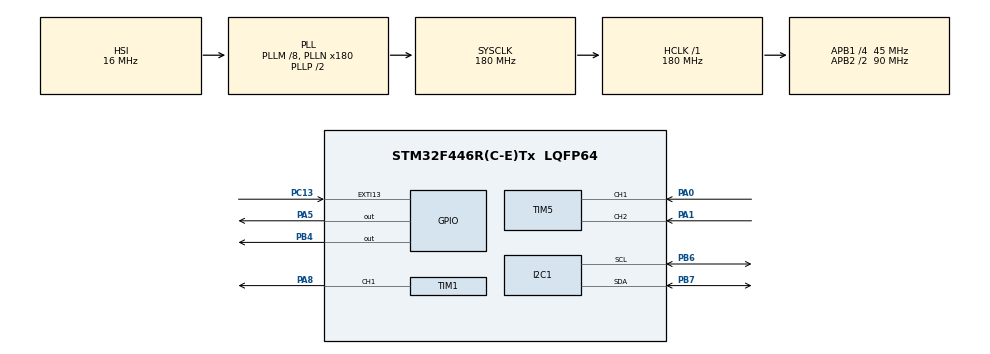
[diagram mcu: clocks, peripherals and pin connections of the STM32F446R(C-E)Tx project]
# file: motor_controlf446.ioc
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Mcu.Family=STM32F4
Mcu.Name=STM32F446R(C-E)Tx
Mcu.Package=LQFP64
NUCLEO-F446RE.BUTTON=1
NUCLEO-F446RE.LD1=true
NVIC.EXTI15_10_IRQn=true\:0\:0\:false\:false\:true\:false\:true\:true
NVIC.PriorityGroup=NVIC_PRIORITYGROUP_0
NVIC.TIM6_DAC_IRQn=true\:0\:0\:false\:false\:true\:true\:true\:true
PA0-WKUP.Signal=S_TIM5_CH1
PA1.Signal=S_TIM5_CH2
PA13.GPIO_Label=TMS
PA13.Signal=SYS_JTMS-SWDIO
PA14.GPIO_Label=TCK
PA14.Signal=SYS_JTCK-SWCLK
PA2.GPIO_Label=USART_TX
PA2.Signal=USART2_TX
PA3.GPIO_Label=USART_RX
PA3.Signal=USART2_RX
PA5.Signal=GPIO_Output
PA8.Signal=S_TIM1_CH1
PB3.GPIO_Label=SWO
PB3.Signal=SYS_JTDO-SWO
PB4.Signal=GPIO_Output
PB6.Mode=I2C
PB6.Signal=I2C1_SCL
PB7.Mode=I2C
PB7.Signal=I2C1_SDA
PC13.Signal=GPXTI13
PC14-OSC32_IN.Signal=RCC_OSC32_IN
PC15-OSC32_OUT.Signal=RCC_OSC32_OUT
PH0-OSC_IN.Signal=RCC_OSC_IN
PH1-OSC_OUT.Signal=RCC_OSC_OUT
ProjectManager.HeapSize=0x200
ProjectManager.StackSize=0x400
ProjectManager.TargetToolchain=STM32CubeIDE
RCC.AHBFreq_Value=180000000
RCC.APB1CLKDivider=RCC_HCLK_DIV4
RCC.APB1Freq_Value=45000000
RCC.APB1TimFreq_Value=90000000
RCC.APB2CLKDivider=RCC_HCLK_DIV2
RCC.APB2Freq_Value=90000000
RCC.APB2TimFreq_Value=180000000
RCC.CortexFreq_Value=180000000
RCC.FLatency-AdvancedSettings=FLASH_LATENCY_5
RCC.HCLKFreq_Value=180000000
RCC.HSE_VALUE=8000000
RCC.HSI_VALUE=16000000
RCC.LSE_VALUE=32768
RCC.PLLM=8
RCC.PLLN=180
RCC.SYSCLKFreq_VALUE=180000000
RCC.SYSCLKSource=RCC_SYSCLKSOURCE_PLLCLK
RCC.USBFreq_Value=180000000
RCC.VCOOutputFreq_Value=360000000
SH.S_TIM1_CH1.0=TIM1_CH1,PWM Generation1 CH1
SH.S_TIM5_CH1.0=TIM5_CH1,Encoder_Interface
SH.S_TIM5_CH2.0=TIM5_CH2,Encoder_Interface
TIM1.Channel-PWM\ Generation1\ CH1=TIM_CHANNEL_1
TIM1.Period=4095
TIM1.Prescaler=2-1
TIM5.EncoderMode=TIM_ENCODERMODE_TI12
TIM6.Period=99
TIM6.Prescaler=89
VP_NUCLEO-F446RE_VS_BSP_COMMON.Mode=COMMON
VP_TIM1_VS_ClockSourceINT.Mode=Internal
VP_TIM6_VS_ClockSourceINT.Mode=Enable_Timer
board=NUCLEO-F446RE

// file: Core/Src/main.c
/* USER CODE BEGIN Header */
/**
  ******************************************************************************
  * @file           : main.c
  * @brief          : Main program body
  ******************************************************************************
  * @attention
  *
  * Copyright (c) 2026 STMicroelectronics.
  * All rights reserved.
  *
  * This software is licensed under terms that can be found in the LICENSE file
  * in the root directory of this software component.
  * If no LICENSE file comes with this software, it is provided AS-IS.
  *
  ******************************************************************************
  */
/* USER CODE END Header */
#include "main.h"
#include "i2c.h"
#include "tim.h"
#include "gpio.h"

/* USER CODE BEGIN Includes */
#include "motor_control.h"
#include "gpio.h"
#include "tim.h"
#include <stdio.h>
/* USER CODE END Includes */

/* USER CODE BEGIN PV */
volatile uint16_t encoder_raw_value = 0;
volatile HAL_StatusTypeDef i2c_status = HAL_OK;
volatile uint8_t magnet_status = 0;
/* USER CODE END PV */

void SystemClock_Config(void);

int main(void)
{

  /* MCU Configuration--------------------------------------------------------*/

  /* Reset of all peripherals, Initializes the Flash interface and the Systick. */
  HAL_Init();

  /* Configure the system clock */
  SystemClock_Config();

  /* Initialize all configured peripherals */
  MX_GPIO_Init();
  MX_TIM1_Init();
  MX_TIM5_Init();
  MX_TIM6_Init();
  MX_I2C1_Init();
  /* USER CODE BEGIN 2 */
  // 1. Start PWM Output (PA8)
  HAL_TIM_PWM_Start(&htim1, TIM_CHANNEL_1);

    // 3. Start 10ms Control Loop Interrupt
  HAL_TIM_Base_Start_IT(&htim6);

    // 4. Initialize Motor Control Subsystems
  MotorControl_Init();
  Elbow_Control_Init();
  /* USER CODE END 2 */

  /* Initialize leds */
  BSP_LED_Init(LED2);

  /* Initialize USER push-button, will be used to trigger an interrupt each time it's pressed.*/
  BSP_PB_Init(BUTTON_USER, BUTTON_MODE_EXTI);

  /* Infinite loop */
  while (1)
  {

  }
}

void SystemClock_Config(void)
{
  RCC_OscInitTypeDef RCC_OscInitStruct = {0};
  RCC_ClkInitTypeDef RCC_ClkInitStruct = {0};

  /** Configure the main internal regulator output voltage
  */
  __HAL_RCC_PWR_CLK_ENABLE();
  __HAL_PWR_VOLTAGESCALING_CONFIG(PWR_REGULATOR_VOLTAGE_SCALE1);

  /** Initializes the RCC Oscillators according to the specified parameters
  * in the RCC_OscInitTypeDef structure.
  */
  RCC_OscInitStruct.OscillatorType = RCC_OSCILLATORTYPE_HSI;
  RCC_OscInitStruct.HSIState = RCC_HSI_ON;
  RCC_OscInitStruct.HSICalibrationValue = RCC_HSICALIBRATION_DEFAULT;
  RCC_OscInitStruct.PLL.PLLState = RCC_PLL_ON;
  RCC_OscInitStruct.PLL.PLLSource = RCC_PLLSOURCE_HSI;
  RCC_OscInitStruct.PLL.PLLM = 8;
  RCC_OscInitStruct.PLL.PLLN = 180;
  RCC_OscInitStruct.PLL.PLLP = RCC_PLLP_DIV2;
  RCC_OscInitStruct.PLL.PLLQ = 2;
  RCC_OscInitStruct.PLL.PLLR = 2;
  if (HAL_RCC_OscConfig(&RCC_OscInitStruct) != HAL_OK)
  {
    Error_Handler();
  }

  /** Activate the Over-Drive mode
  */
  if (HAL_PWREx_EnableOverDrive() != HAL_OK)
  {
    Error_Handler();
  }

  /** Initializes the CPU, AHB and APB buses clocks
  */
  RCC_ClkInitStruct.ClockType = RCC_CLOCKTYPE_HCLK|RCC_CLOCKTYPE_SYSCLK
                              |RCC_CLOCKTYPE_PCLK1|RCC_CLOCKTYPE_PCLK2;
  RCC_ClkInitStruct.SYSCLKSource = RCC_SYSCLKSOURCE_PLLCLK;
  RCC_ClkInitStruct.AHBCLKDivider = RCC_SYSCLK_DIV1;
  RCC_ClkInitStruct.APB1CLKDivider = RCC_HCLK_DIV4;
  RCC_ClkInitStruct.APB2CLKDivider = RCC_HCLK_DIV2;

  if (HAL_RCC_ClockConfig(&RCC_ClkInitStruct, FLASH_LATENCY_5) != HAL_OK)
  {
    Error_Handler();
  }
}

/* USER CODE BEGIN 4 */
void HAL_TIM_PeriodElapsedCallback(TIM_HandleTypeDef *htim)
{
    if (htim->Instance == TIM6) // 100us Interrupt
    {
        MotorControl_Update(0.001f);

        // Disabled: prevents elbowMotor from overwriting PA8 PWM and PB4 direction pin
        // float target_pos = 2000.0f;
        // Elbow_Control_Update(target_pos, 0.01f);
    }
}
/* USER CODE END 4 */

void Error_Handler(void)
{
  __disable_irq();
  while (1)
  {
  }
}
